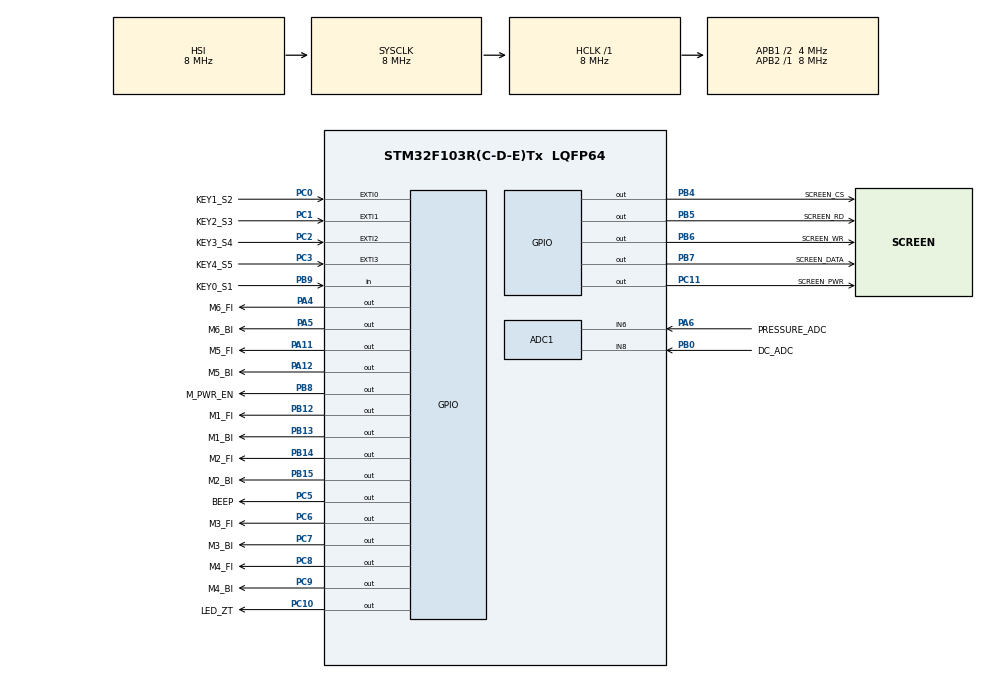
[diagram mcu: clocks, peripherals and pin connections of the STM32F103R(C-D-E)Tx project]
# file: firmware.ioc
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ADC1.Channel-11\#ChannelRegularConversion=ADC_CHANNEL_8
ADC1.Channel-12\#ChannelRegularConversion=ADC_CHANNEL_6
ADC1.ContinuousConvMode=ENABLE
ADC1.EnableInjectedConversion=DISABLE
ADC1.EnableRegularConversion=ENABLE
ADC1.NbrOfConversion=2
ADC1.NbrOfConversionFlag=1
ADC1.Rank-11\#ChannelRegularConversion=1
ADC1.Rank-12\#ChannelRegularConversion=2
ADC1.SamplingTime-11\#ChannelRegularConversion=ADC_SAMPLETIME_239CYCLES_5
ADC1.SamplingTime-12\#ChannelRegularConversion=ADC_SAMPLETIME_239CYCLES_5
ADC1.master=1
Dma.ADC1.0.Direction=DMA_PERIPH_TO_MEMORY
Dma.ADC1.0.Instance=DMA1_Channel1
Dma.ADC1.0.MemDataAlignment=DMA_MDATAALIGN_HALFWORD
Dma.ADC1.0.MemInc=DMA_MINC_ENABLE
Dma.ADC1.0.Mode=DMA_CIRCULAR
Dma.ADC1.0.PeriphDataAlignment=DMA_PDATAALIGN_HALFWORD
Dma.ADC1.0.PeriphInc=DMA_PINC_DISABLE
Dma.ADC1.0.Priority=DMA_PRIORITY_LOW
Dma.Request0=ADC1
Mcu.Family=STM32F1
Mcu.Name=STM32F103R(C-D-E)Tx
Mcu.Package=LQFP64
NVIC.DMA1_Channel1_IRQn=true\:0\:0\:false\:false\:true\:true\:false\:true\:true
NVIC.EXTI0_IRQn=true\:0\:0\:false\:false\:true\:false\:true\:true\:true
NVIC.EXTI1_IRQn=true\:0\:0\:false\:false\:true\:false\:true\:true\:true
NVIC.EXTI2_IRQn=true\:0\:0\:false\:false\:true\:false\:true\:true\:true
NVIC.EXTI3_IRQn=true\:0\:0\:false\:false\:true\:false\:true\:true\:true
NVIC.PriorityGroup=NVIC_PRIORITYGROUP_4
NVIC.RTC_IRQn=true\:0\:0\:false\:false\:true\:false\:true\:true\:true
PA11.GPIO_Label=M5_FI
PA11.Signal=GPIO_Output
PA12.GPIO_Label=M5_BI
PA12.Signal=GPIO_Output
PA13.Mode=Serial_Wire
PA13.Signal=SYS_JTMS-SWDIO
PA14.Mode=Serial_Wire
PA14.Signal=SYS_JTCK-SWCLK
PA4.GPIO_Label=M6_FI
PA4.Signal=GPIO_Output
PA5.GPIO_Label=M6_BI
PA5.Signal=GPIO_Output
PA6.GPIO_Label=PRESSURE_ADC
PA6.Signal=ADCx_IN6
PB0.GPIO_Label=DC_ADC
PB0.Signal=ADCx_IN8
PB12.GPIO_Label=M1_FI
PB12.Signal=GPIO_Output
PB13.GPIO_Label=M1_BI
PB13.Signal=GPIO_Output
PB14.GPIO_Label=M2_FI
PB14.Signal=GPIO_Output
PB15.GPIO_Label=M2_BI
PB15.Signal=GPIO_Output
PB4.GPIO_Label=SCREEN_CS
PB4.Signal=GPIO_Output
PB5.GPIO_Label=SCREEN_RD
PB5.Signal=GPIO_Output
PB6.GPIO_Label=SCREEN_WR
PB6.Signal=GPIO_Output
PB7.GPIO_Label=SCREEN_DATA
PB7.Signal=GPIO_Output
PB8.GPIO_Label=M_PWR_EN
PB8.Signal=GPIO_Output
PB9.GPIO_Label=KEY0_S1
PB9.Signal=GPIO_Input
PC0.GPIO_Label=KEY1_S2
PC0.Signal=GPXTI0
PC1.GPIO_Label=KEY2_S3
PC1.Signal=GPXTI1
PC10.GPIO_Label=LED_ZT
PC10.Signal=GPIO_Output
PC11.GPIO_Label=SCREEN_PWR
PC11.GPIO_PuPd=GPIO_NOPULL
PC11.Signal=GPIO_Output
PC14-OSC32_IN.Mode=LSE-External-Oscillator
PC14-OSC32_IN.Signal=RCC_OSC32_IN
PC15-OSC32_OUT.Mode=LSE-External-Oscillator
PC15-OSC32_OUT.Signal=RCC_OSC32_OUT
PC2.GPIO_Label=KEY3_S4
PC2.Signal=GPXTI2
PC3.GPIO_Label=KEY4_S5
PC3.Signal=GPXTI3
PC5.GPIO_Label=BEEP
PC5.Signal=GPIO_Output
PC6.GPIO_Label=M3_FI
PC6.Signal=GPIO_Output
PC7.GPIO_Label=M3_BI
PC7.Signal=GPIO_Output
PC8.GPIO_Label=M4_FI
PC8.Signal=GPIO_Output
PC9.GPIO_Label=M4_BI
PC9.Signal=GPIO_Output
ProjectManager.HeapSize=0x200
ProjectManager.StackSize=0x400
ProjectManager.TargetToolchain=MDK-ARM V5.32
RCC.AHBFreq_Value=8000000
RCC.APB1CLKDivider=RCC_HCLK_DIV2
RCC.APB1Freq_Value=4000000
RCC.APB1TimFreq_Value=8000000
RCC.APB2Freq_Value=8000000
RCC.APB2TimFreq_Value=8000000
RCC.HCLKFreq_Value=8000000
RCC.PLLMUL=RCC_PLL_MUL16
RCC.RTCClockSelection=RCC_RTCCLKSOURCE_LSE
RCC.SYSCLKFreq_VALUE=8000000
RCC.USBFreq_Value=64000000
RealThread.X-CUBE-RT-Thread_Nano.4.1.1.RTAaThreadCcRTOSJjdevice=true
RealThread.X-CUBE-RT-Thread_Nano.4.1.1.RTAaThreadCcRTOSJjkernel=true
RealThread.X-CUBE-RT-Thread_Nano.4.1.1.RTAaThreadCcRTOSJjlibcpu=true
RealThread.X-CUBE-RT-Thread_Nano.4.1.1.RTAaThreadCcRTOSJjshell=true
RealThread.X-CUBE-RT-Thread_Nano.4.1.1.RT_USING_CONSOLE=0
RealThread.X-CUBE-RT-Thread_Nano.4.1.1.RT_USING_FINSH=0
RealThread.X-CUBE-RT-Thread_Nano.4.1.1.RT_USING_MESSAGEQUEUE=1
RealThread.X-CUBE-RT-Thread_Nano.4.1.1.RT_USING_MUTEX=1
RealThread.X-CUBE-RT-Thread_Nano.4.1.1.RT_USING_SEMAPHORE=0
RealThread.X-CUBE-RT-Thread_Nano.4.1.1.RT_USING_TIMER_SOFT=1
SH.ADCx_IN6.0=ADC1_IN6,IN6
SH.ADCx_IN8.0=ADC1_IN8,IN8
VP_RTC_VS_RTC_Activate.Mode=RTC_Enabled
VP_RealThread.X-CUBE-RT-Thread_Nano_VS_RTOSJjRTAaThread_4.1.1_4.1.1.Mode=RTOSJjRTAaThread
board=custom

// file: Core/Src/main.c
/* USER CODE BEGIN Header */
/**
  ******************************************************************************
  * @file           : main.c
  * @brief          : Main program body
  ******************************************************************************
  * @attention
  *
  * Copyright (c) 2026 STMicroelectronics.
  * All rights reserved.
  *
  * This software is licensed under terms that can be found in the LICENSE file
  * in the root directory of this software component.
  * If no LICENSE file comes with this software, it is provided AS-IS.
  *
  ******************************************************************************
  */
/* USER CODE END Header */
#include "main.h"

/* USER CODE BEGIN Includes */
#include "rtthread.h"
#include "pwr.h"
/* USER CODE END Includes */

ADC_HandleTypeDef hadc1;
DMA_HandleTypeDef hdma_adc1;

RTC_HandleTypeDef hrtc;

void SystemClock_Config(void);
static void MX_GPIO_Init(void);
static void MX_DMA_Init(void);
static void MX_ADC1_Init(void);
static void MX_RTC_Init(void);

int main(void)
{

  /* MCU Configuration--------------------------------------------------------*/

  /* Reset of all peripherals, Initializes the Flash interface and the Systick. */
  HAL_Init();

  /* Configure the system clock */
  SystemClock_Config();

  /* Initialize all configured peripherals */
  MX_GPIO_Init();
  MX_DMA_Init();
  MX_ADC1_Init();
  MX_RTC_Init();

  /* Infinite loop */
  /* USER CODE BEGIN WHILE */
  #if 0
  while (1)
  {

    /* USER CODE END WHILE */

    /* USER CODE BEGIN 3 */
  }
  #endif
  /* USER CODE END 3 */
}

void SystemClock_Config(void)
{
  RCC_OscInitTypeDef RCC_OscInitStruct = {0};
  RCC_ClkInitTypeDef RCC_ClkInitStruct = {0};
  RCC_PeriphCLKInitTypeDef PeriphClkInit = {0};

  /** Initializes the RCC Oscillators according to the specified parameters
  * in the RCC_OscInitTypeDef structure.
  */
  RCC_OscInitStruct.OscillatorType = RCC_OSCILLATORTYPE_HSI|RCC_OSCILLATORTYPE_LSE;
  RCC_OscInitStruct.LSEState = RCC_LSE_ON;
  RCC_OscInitStruct.HSIState = RCC_HSI_ON;
  RCC_OscInitStruct.HSICalibrationValue = RCC_HSICALIBRATION_DEFAULT;
  RCC_OscInitStruct.PLL.PLLState = RCC_PLL_NONE;
  if (HAL_RCC_OscConfig(&RCC_OscInitStruct) != HAL_OK)
  {
    Error_Handler();
  }

  /** Initializes the CPU, AHB and APB buses clocks
  */
  RCC_ClkInitStruct.ClockType = RCC_CLOCKTYPE_HCLK|RCC_CLOCKTYPE_SYSCLK
                              |RCC_CLOCKTYPE_PCLK1|RCC_CLOCKTYPE_PCLK2;
  RCC_ClkInitStruct.SYSCLKSource = RCC_SYSCLKSOURCE_HSI;
  RCC_ClkInitStruct.AHBCLKDivider = RCC_SYSCLK_DIV1;
  RCC_ClkInitStruct.APB1CLKDivider = RCC_HCLK_DIV2;
  RCC_ClkInitStruct.APB2CLKDivider = RCC_HCLK_DIV1;

  if (HAL_RCC_ClockConfig(&RCC_ClkInitStruct, FLASH_LATENCY_0) != HAL_OK)
  {
    Error_Handler();
  }
  PeriphClkInit.PeriphClockSelection = RCC_PERIPHCLK_RTC|RCC_PERIPHCLK_ADC;
  PeriphClkInit.RTCClockSelection = RCC_RTCCLKSOURCE_LSE;
  PeriphClkInit.AdcClockSelection = RCC_ADCPCLK2_DIV2;
  if (HAL_RCCEx_PeriphCLKConfig(&PeriphClkInit) != HAL_OK)
  {
    Error_Handler();
  }
}

static void MX_ADC1_Init(void)
{

  ADC_ChannelConfTypeDef sConfig = {0};

  /** Common config
  */
  hadc1.Instance = ADC1;
  hadc1.Init.ScanConvMode = ADC_SCAN_ENABLE;
  hadc1.Init.ContinuousConvMode = ENABLE;
  hadc1.Init.DiscontinuousConvMode = DISABLE;
  hadc1.Init.ExternalTrigConv = ADC_SOFTWARE_START;
  hadc1.Init.DataAlign = ADC_DATAALIGN_RIGHT;
  hadc1.Init.NbrOfConversion = 2;
  if (HAL_ADC_Init(&hadc1) != HAL_OK)
  {
    Error_Handler();
  }

  /** Configure Regular Channel
  */
  sConfig.Channel = ADC_CHANNEL_8;
  sConfig.Rank = ADC_REGULAR_RANK_1;
  sConfig.SamplingTime = ADC_SAMPLETIME_239CYCLES_5;
  if (HAL_ADC_ConfigChannel(&hadc1, &sConfig) != HAL_OK)
  {
    Error_Handler();
  }

  /** Configure Regular Channel
  */
  sConfig.Channel = ADC_CHANNEL_6;
  sConfig.Rank = ADC_REGULAR_RANK_2;
  if (HAL_ADC_ConfigChannel(&hadc1, &sConfig) != HAL_OK)
  {
    Error_Handler();
  }
  /* USER CODE BEGIN ADC1_Init 2 */
  	HAL_ADCEx_Calibration_Start(&hadc1);
	HAL_ADC_Start_DMA(&hadc1, (rt_uint32_t*)adc_value, ADC_BUF_SIZE*2);
  /* USER CODE END ADC1_Init 2 */

}

static void MX_RTC_Init(void)
{

  /** Initialize RTC Only
  */
  hrtc.Instance = RTC;
  hrtc.Init.AsynchPrediv = RTC_AUTO_1_SECOND;
  hrtc.Init.OutPut = RTC_OUTPUTSOURCE_ALARM;
  if (HAL_RTC_Init(&hrtc) != HAL_OK)
  {
    Error_Handler();
  }
  /* USER CODE BEGIN RTC_Init 2 */
	HAL_RTCEx_SetSecond_IT(&hrtc);
  /* USER CODE END RTC_Init 2 */

}

static void MX_DMA_Init(void)
{

  /* DMA controller clock enable */
  __HAL_RCC_DMA1_CLK_ENABLE();

  /* DMA interrupt init */
  /* DMA1_Channel1_IRQn interrupt configuration */
  HAL_NVIC_SetPriority(DMA1_Channel1_IRQn, 0, 0);
  HAL_NVIC_EnableIRQ(DMA1_Channel1_IRQn);

}

static void MX_GPIO_Init(void)
{
  GPIO_InitTypeDef GPIO_InitStruct = {0};

  /* GPIO Ports Clock Enable */
  __HAL_RCC_GPIOC_CLK_ENABLE();
  __HAL_RCC_GPIOA_CLK_ENABLE();
  __HAL_RCC_GPIOB_CLK_ENABLE();

  /*Configure GPIO pin Output Level */
  HAL_GPIO_WritePin(GPIOA, M6_FI_Pin|M6_BI_Pin|M5_FI_Pin|M5_BI_Pin, GPIO_PIN_RESET);

  /*Configure GPIO pin Output Level */
  HAL_GPIO_WritePin(GPIOC, BEEP_Pin|M3_FI_Pin|M3_BI_Pin|M4_FI_Pin
                          |M4_BI_Pin|LED_ZT_Pin|SCREEN_PWR_Pin, GPIO_PIN_RESET);

  /*Configure GPIO pin Output Level */
  HAL_GPIO_WritePin(GPIOB, M1_FI_Pin|M1_BI_Pin|M2_FI_Pin|M2_BI_Pin
                          |SCREEN_CS_Pin|SCREEN_RD_Pin|SCREEN_WR_Pin|SCREEN_DATA_Pin
                          |M_PWR_EN_Pin, GPIO_PIN_RESET);

  /*Configure GPIO pins : KEY1_S2_Pin KEY2_S3_Pin KEY3_S4_Pin KEY4_S5_Pin */
  GPIO_InitStruct.Pin = KEY1_S2_Pin|KEY2_S3_Pin|KEY3_S4_Pin|KEY4_S5_Pin;
  GPIO_InitStruct.Mode = GPIO_MODE_IT_RISING;
  GPIO_InitStruct.Pull = GPIO_NOPULL;
  HAL_GPIO_Init(GPIOC, &GPIO_InitStruct);

  /*Configure GPIO pins : M6_FI_Pin M6_BI_Pin M5_FI_Pin M5_BI_Pin */
  GPIO_InitStruct.Pin = M6_FI_Pin|M6_BI_Pin|M5_FI_Pin|M5_BI_Pin;
  GPIO_InitStruct.Mode = GPIO_MODE_OUTPUT_PP;
  GPIO_InitStruct.Pull = GPIO_NOPULL;
  GPIO_InitStruct.Speed = GPIO_SPEED_FREQ_LOW;
  HAL_GPIO_Init(GPIOA, &GPIO_InitStruct);

  /*Configure GPIO pins : BEEP_Pin M3_FI_Pin M3_BI_Pin M4_FI_Pin
                           M4_BI_Pin LED_ZT_Pin SCREEN_PWR_Pin */
  GPIO_InitStruct.Pin = BEEP_Pin|M3_FI_Pin|M3_BI_Pin|M4_FI_Pin
                          |M4_BI_Pin|LED_ZT_Pin|SCREEN_PWR_Pin;
  GPIO_InitStruct.Mode = GPIO_MODE_OUTPUT_PP;
  GPIO_InitStruct.Pull = GPIO_NOPULL;
  GPIO_InitStruct.Speed = GPIO_SPEED_FREQ_LOW;
  HAL_GPIO_Init(GPIOC, &GPIO_InitStruct);

  /*Configure GPIO pins : M1_FI_Pin M1_BI_Pin M2_FI_Pin M2_BI_Pin
                           SCREEN_CS_Pin SCREEN_RD_Pin SCREEN_WR_Pin SCREEN_DATA_Pin
                           M_PWR_EN_Pin */
  GPIO_InitStruct.Pin = M1_FI_Pin|M1_BI_Pin|M2_FI_Pin|M2_BI_Pin
                          |SCREEN_CS_Pin|SCREEN_RD_Pin|SCREEN_WR_Pin|SCREEN_DATA_Pin
                          |M_PWR_EN_Pin;
  GPIO_InitStruct.Mode = GPIO_MODE_OUTPUT_PP;
  GPIO_InitStruct.Pull = GPIO_NOPULL;
  GPIO_InitStruct.Speed = GPIO_SPEED_FREQ_LOW;
  HAL_GPIO_Init(GPIOB, &GPIO_InitStruct);

  /*Configure GPIO pin : KEY0_S1_Pin */
  GPIO_InitStruct.Pin = KEY0_S1_Pin;
  GPIO_InitStruct.Mode = GPIO_MODE_INPUT;
  GPIO_InitStruct.Pull = GPIO_NOPULL;
  HAL_GPIO_Init(KEY0_S1_GPIO_Port, &GPIO_InitStruct);

  /* EXTI interrupt init*/
  HAL_NVIC_SetPriority(EXTI0_IRQn, 0, 0);
  HAL_NVIC_EnableIRQ(EXTI0_IRQn);

  HAL_NVIC_SetPriority(EXTI1_IRQn, 0, 0);
  HAL_NVIC_EnableIRQ(EXTI1_IRQn);

  HAL_NVIC_SetPriority(EXTI2_IRQn, 0, 0);
  HAL_NVIC_EnableIRQ(EXTI2_IRQn);

  HAL_NVIC_SetPriority(EXTI3_IRQn, 0, 0);
  HAL_NVIC_EnableIRQ(EXTI3_IRQn);

}

void Error_Handler(void)
{
  __disable_irq();
  while (1)
  {
  }
}
